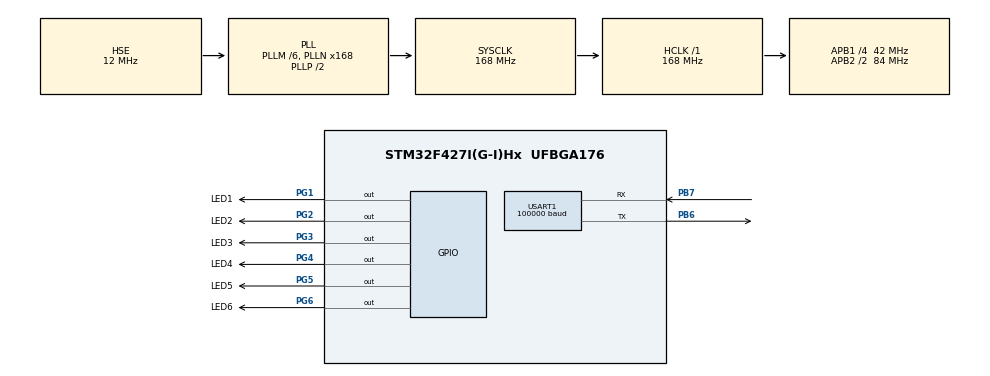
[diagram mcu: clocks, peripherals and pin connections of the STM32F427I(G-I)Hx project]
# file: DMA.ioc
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Dma.Request0=USART1_RX
Dma.USART1_RX.0.Direction=DMA_PERIPH_TO_MEMORY
Dma.USART1_RX.0.FIFOMode=DMA_FIFOMODE_DISABLE
Dma.USART1_RX.0.Instance=DMA2_Stream2
Dma.USART1_RX.0.MemDataAlignment=DMA_MDATAALIGN_BYTE
Dma.USART1_RX.0.MemInc=DMA_MINC_ENABLE
Dma.USART1_RX.0.Mode=DMA_NORMAL
Dma.USART1_RX.0.PeriphDataAlignment=DMA_PDATAALIGN_BYTE
Dma.USART1_RX.0.PeriphInc=DMA_PINC_DISABLE
Dma.USART1_RX.0.Priority=DMA_PRIORITY_VERY_HIGH
Mcu.Family=STM32F4
Mcu.Name=STM32F427I(G-I)Hx
Mcu.Package=UFBGA176
NVIC.DMA2_Stream2_IRQn=true\:0\:0\:false\:false\:true\:false\:true
NVIC.PriorityGroup=NVIC_PRIORITYGROUP_4
NVIC.USART1_IRQn=true\:0\:0\:false\:false\:true\:true\:true
PB6.Mode=Asynchronous
PB6.Signal=USART1_TX
PB7.Mode=Asynchronous
PB7.Signal=USART1_RX
PG1.GPIO_Label=LED1
PG1.Signal=GPIO_Output
PG2.GPIO_Label=LED2
PG2.Signal=GPIO_Output
PG3.GPIO_Label=LED3
PG3.Signal=GPIO_Output
PG4.GPIO_Label=LED4
PG4.Signal=GPIO_Output
PG5.GPIO_Label=LED5
PG5.Signal=GPIO_Output
PG6.GPIO_Label=LED6
PG6.Signal=GPIO_Output
PH0/OSC_IN.Mode=HSE-External-Oscillator
PH0/OSC_IN.Signal=RCC_OSC_IN
PH1/OSC_OUT.Mode=HSE-External-Oscillator
PH1/OSC_OUT.Signal=RCC_OSC_OUT
ProjectManager.HeapSize=0x200
ProjectManager.StackSize=0x1000
ProjectManager.TargetToolchain=MDK-ARM V5.27
RCC.48MHZClocksFreq_Value=84000000
RCC.AHBFreq_Value=168000000
RCC.APB1CLKDivider=RCC_HCLK_DIV4
RCC.APB1Freq_Value=42000000
RCC.APB1TimFreq_Value=84000000
RCC.APB2CLKDivider=RCC_HCLK_DIV2
RCC.APB2Freq_Value=84000000
RCC.APB2TimFreq_Value=168000000
RCC.CortexFreq_Value=168000000
RCC.HCLKFreq_Value=168000000
RCC.HSE_VALUE=12000000
RCC.HSI_VALUE=16000000
RCC.LSE_VALUE=32768
RCC.PLLM=6
RCC.PLLN=168
RCC.PLLSourceVirtual=RCC_PLLSOURCE_HSE
RCC.SYSCLKFreq_VALUE=168000000
RCC.SYSCLKSource=RCC_SYSCLKSOURCE_PLLCLK
RCC.VCOOutputFreq_Value=336000000
USART1.BaudRate=100000
USART1.VirtualMode=VM_ASYNC
board=custom

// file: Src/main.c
/* USER CODE BEGIN Header */
/**
  ******************************************************************************
  * @file           : main.c
  * @brief          : Main program body
  ******************************************************************************
  * @attention
  *
  * <h2><center>&copy; Copyright (c) 2020 STMicroelectronics.
  * All rights reserved.</center></h2>
  *
  * This software component is licensed by ST under BSD 3-Clause license,
  * the "License"; You may not use this file except in compliance with the
  * License. You may obtain a copy of the License at:
  *                        opensource.org/licenses/BSD-3-Clause
  *
  ******************************************************************************
  */
/* USER CODE END Header */

#include "main.h"
#include "dma.h"
#include "usart.h"
#include "gpio.h"

/* USER CODE BEGIN Includes */
extern DMA_HandleTypeDef hdma_usart1_rx;
/* USER CODE END Includes */

/* USER CODE BEGIN PTD */
uint8_t mask = 0x3;
/* USER CODE END PTD */

/* USER CODE BEGIN PD */
uint8_t dmaRxBuffer[2][18];
uint8_t dmaData[18];
/* USER CODE END PD */

void SystemClock_Config(void);

int main(void)
{

  /* MCU Configuration--------------------------------------------------------*/

  /* Reset of all peripherals, Initializes the Flash interface and the Systick. */
  HAL_Init();

  /* Configure the system clock */
  SystemClock_Config();

  /* Initialize all configured peripherals */
  MX_GPIO_Init();
  MX_DMA_Init();
  MX_USART1_UART_Init();
  /* USER CODE BEGIN 2 */
	//HAL_UART_Receive_DMA(&huart1, dmaRxBuffer, 18);
  /* USER CODE END 2 */
 // DMA settings
	// Enable the DMA transfer for the receiver request
	SET_BIT(huart1.Instance->CR3, USART_CR3_DMAR);

	// Enable idle interrupt
	__HAL_UART_ENABLE_IT(&huart1, UART_IT_IDLE);

	// Disable DMA
	__HAL_DMA_DISABLE(&hdma_usart1_rx);

	while(hdma_usart1_rx.Instance->CR & DMA_SxCR_EN)
	{
	__HAL_DMA_DISABLE(&hdma_usart1_rx);
	}

	hdma_usart1_rx.Instance->PAR = (uint32_t)&(USART1->DR);

	hdma_usart1_rx.Instance->M0AR = (uint32_t) dmaRxBuffer[0];

	hdma_usart1_rx.Instance->M1AR = (uint32_t) dmaRxBuffer[1];

	hdma_usart1_rx.Instance->NDTR = 36;

	// Enable double memory buffer
	SET_BIT(hdma_usart1_rx.Instance->CR, DMA_SxCR_DBM);

	// Enable DMA
	__HAL_DMA_ENABLE(&hdma_usart1_rx);

  /* Infinite loop */
  while (1)
  {
		if (((dmaData[5] >> 6) & mask) == 0x3)
		{
			HAL_GPIO_WritePin(LED1_GPIO_Port, LED1_Pin, GPIO_PIN_SET);
			HAL_GPIO_WritePin(LED2_GPIO_Port, LED2_Pin, GPIO_PIN_RESET);
			HAL_GPIO_WritePin(LED3_GPIO_Port, LED3_Pin, GPIO_PIN_SET);
		}
		else if (((dmaData[5] >> 6) & mask) == 0x2)
		{
			HAL_GPIO_WritePin(LED1_GPIO_Port, LED1_Pin, GPIO_PIN_RESET);
			HAL_GPIO_WritePin(LED2_GPIO_Port, LED2_Pin, GPIO_PIN_SET);
			HAL_GPIO_WritePin(LED3_GPIO_Port, LED3_Pin, GPIO_PIN_SET);
		}
		else
		{
			HAL_GPIO_WritePin(LED1_GPIO_Port, LED1_Pin, GPIO_PIN_SET);
			HAL_GPIO_WritePin(LED2_GPIO_Port, LED2_Pin, GPIO_PIN_SET);
			HAL_GPIO_WritePin(LED3_GPIO_Port, LED3_Pin, GPIO_PIN_RESET);
		}

		if (((dmaData[5] >> 4) & mask) == 0x3)
		{
			HAL_GPIO_WritePin(LED4_GPIO_Port, LED4_Pin, GPIO_PIN_RESET);
			HAL_GPIO_WritePin(LED5_GPIO_Port, LED5_Pin, GPIO_PIN_SET);
			HAL_GPIO_WritePin(LED6_GPIO_Port, LED6_Pin, GPIO_PIN_SET);
		}
		else if (((dmaData[5] >> 4) & mask) == 0x2)
		{
			HAL_GPIO_WritePin(LED4_GPIO_Port, LED4_Pin, GPIO_PIN_SET);
			HAL_GPIO_WritePin(LED5_GPIO_Port, LED5_Pin, GPIO_PIN_RESET);
			HAL_GPIO_WritePin(LED6_GPIO_Port, LED6_Pin, GPIO_PIN_SET);
		}
		else
		{
			HAL_GPIO_WritePin(LED4_GPIO_Port, LED4_Pin, GPIO_PIN_SET);
			HAL_GPIO_WritePin(LED5_GPIO_Port, LED5_Pin, GPIO_PIN_SET);
			HAL_GPIO_WritePin(LED6_GPIO_Port, LED6_Pin, GPIO_PIN_RESET);
		}

		HAL_Delay(10);
  }
}

void SystemClock_Config(void)
{
  RCC_OscInitTypeDef RCC_OscInitStruct = {0};
  RCC_ClkInitTypeDef RCC_ClkInitStruct = {0};

  /** Configure the main internal regulator output voltage
  */
  __HAL_RCC_PWR_CLK_ENABLE();
  __HAL_PWR_VOLTAGESCALING_CONFIG(PWR_REGULATOR_VOLTAGE_SCALE1);
  /** Initializes the CPU, AHB and APB busses clocks
  */
  RCC_OscInitStruct.OscillatorType = RCC_OSCILLATORTYPE_HSE;
  RCC_OscInitStruct.HSEState = RCC_HSE_ON;
  RCC_OscInitStruct.PLL.PLLState = RCC_PLL_ON;
  RCC_OscInitStruct.PLL.PLLSource = RCC_PLLSOURCE_HSE;
  RCC_OscInitStruct.PLL.PLLM = 6;
  RCC_OscInitStruct.PLL.PLLN = 168;
  RCC_OscInitStruct.PLL.PLLP = RCC_PLLP_DIV2;
  RCC_OscInitStruct.PLL.PLLQ = 4;
  if (HAL_RCC_OscConfig(&RCC_OscInitStruct) != HAL_OK)
  {
    Error_Handler();
  }
  /** Initializes the CPU, AHB and APB busses clocks
  */
  RCC_ClkInitStruct.ClockType = RCC_CLOCKTYPE_HCLK|RCC_CLOCKTYPE_SYSCLK
                              |RCC_CLOCKTYPE_PCLK1|RCC_CLOCKTYPE_PCLK2;
  RCC_ClkInitStruct.SYSCLKSource = RCC_SYSCLKSOURCE_PLLCLK;
  RCC_ClkInitStruct.AHBCLKDivider = RCC_SYSCLK_DIV1;
  RCC_ClkInitStruct.APB1CLKDivider = RCC_HCLK_DIV4;
  RCC_ClkInitStruct.APB2CLKDivider = RCC_HCLK_DIV2;

  if (HAL_RCC_ClockConfig(&RCC_ClkInitStruct, FLASH_LATENCY_5) != HAL_OK)
  {
    Error_Handler();
  }
}

void Error_Handler(void)
{
}

/************************ (C) COPYRIGHT STMicroelectronics *****END OF FILE****/
